# DBGSS register map
Vendor: Texas Instruments
Peripheral module from a debugger description file (folder CC27xxx10).
Registers are 32-bit, access per field, reset 0x0 unless marked. A register's access mark holds for its fields unless they carry their own. Offsets are as the file gives them; lines under a group give offsets from that group; [hi:lo] are bit positions; {n}, {i} and the like mark numbered series; 'fields as' and 'values as' point back to an identical list; <NAME> marks a mode.

## DBGSS
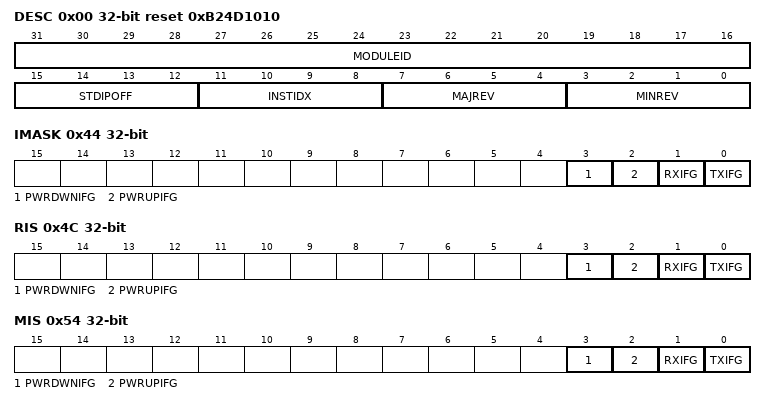
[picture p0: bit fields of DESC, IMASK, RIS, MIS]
0x00 DESC ro reset 0xB24D1010 — Description Register. This register provides IP module ID, revision information, instance index and standard MMR registers offset.
  [31:16] MODULEID — Module identifier used to uniquely identify this IP.
    0xFFFF=MAX (Maximum possible value); 0=MIN (Minimum value)
  [15:12] STDIPOFF — Standard IP MMR block offset. Standard IP MMRs are the set of from aggregated IRQ registers till DTB. 0: Standard IP MMRs do not exist 0x1-0xF: Standard IP MMRs begin at offset of (64*STDIPOFF from the base IP address) 0: STDIP MMRs do not exist 0x1-0xF: These MMRs begin at offset 64*STDIPOFF from IP base address
    15=MAX (Maximum possible value); 0=MIN (Minimum Value)
  [11:8] INSTIDX — IP Instance ID number. If multiple instances of IP exist in the device, this field can identify the instance number (0-15).
    15=MAX (Maximum possible value); 0=MIN (Minimum Value)
  [7:4] MAJREV — Major revision of IP (0-15).
    15=MAX (Maximum possible value); 0=MIN (Minimum Value)
  [3:0] MINREV — Minor revision of IP (0-15).
    15=MAX (Maximum possible value); 0=MIN (Minimum Value)
0x44 IMASK — Interrupt mask. This register selects interrupt sources which are allowed to pass from RIS to MIS when the corresponding bit-fields are set to 1.
  [3] PWRDWNIFG rw — PWRDWNIFG interrupt mask
    1=SET (Interrupt will request an interrupt service routine and corresponding bit in MIS will be set); 0=CLR (Interrupt is masked out)
  [2] PWRUPIFG rw — PWRUPIFG interrupt mask
    values as PWRDWNIFG
  [1] RXIFG rw — RXIFG interrupt mask
    values as PWRDWNIFG
  [0] TXIFG rw — TXIFG interrupt mask
    1=EN (Enable Interrupt Mask); 0=DIS (Disable Interrupt Mask)
0x4C RIS ro — Raw interrupt status. This register reflects the state of all pending interrupts, regardless of masking. This register allows the user to implement a poll scheme. A flag set in this register can be cleared by writing 1 to the corresponding ICLR register bit.
  [3] PWRDWNIFG — Raw interrupt status for PWRDWNIFG
    1=SET (PWRDWNIFG occurred); 0=CLR (PWRDWNIFG did not occur)
  [2] PWRUPIFG — Raw interrupt status for PWRUPIFG
    1=SET (PWRUPIFG occurred); 0=CLR (PWRUPIFG did not occur)
  [1] RXIFG — Raw interrupt status for RXIFG
    1=SET (RXIFG occurred); 0=CLR (RXIFG did not occur)
  [0] TXIFG — Raw interrupt status for TXIFG
    1=SET (TXIFG occurred); 0=CLR (TXIFG did not occur)
0x54 MIS ro — Masked interrupt status. This register is simply a bitwise AND of the contents of IMASK and RIS registers. A flag set in this register can be cleared by writing 1 to the corresponding ICLR register bit.
  [3] PWRDWNIFG — Masked interrupt status for PWRDWNIFG
    1=SET (PWRDWNIFG requests an interrupt service routine); 0=CLR (PWRDWNIFG did not request an interrupt service routine)
  [2] PWRUPIFG — Masked interrupt status for PWRUPIFG
    1=SET (PWRUPIFG requests an interrupt service routine); 0=CLR (PWRUPIFG did not request an interrupt service routine)
  [1] RXIFG — Masked interrupt status for RXIFG
    1=SET (RXIFG requests an interrupt service routine); 0=CLR (RXIFG did not request an interrupt service routine)
  [0] TXIFG — Masked interrupt status for TXIFG
    1=SET (TXIFG requests an interrupt service routine); 0=CLR (TXIFG did not request an interrupt service routine)
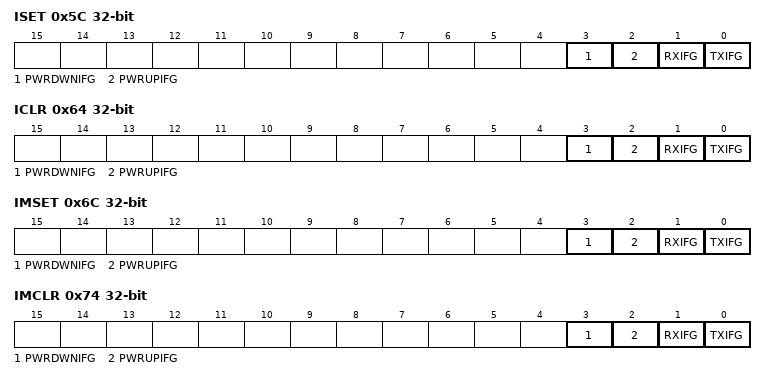
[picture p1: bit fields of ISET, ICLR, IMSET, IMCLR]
0x5C ISET — Interrupt set register. This register can be used by software for diagnostics and safety checking purposes. Writing a 1 to a bit in this register will set the event and the corresponding RIS bit also gets set. If the corresponding IMASK bit is set, then the corresponding MIS register bit also gets set.
  [all] fields
    1=SET (Set interrupt); 0=NOEFF (Writing a 0 has no effect)
  [3] PWRDWNIFG wo — Sets PWRDWNIFG in RIS register
  [2] PWRUPIFG wo — Sets PWRUPIFG in RIS register
  [1] RXIFG wo — Sets RXIFG in RIS register
  [0] TXIFG wo — Sets TXIFG in RIS register
0x64 ICLR — Interrupt clear register. This register allows software to clear interrupts. Writing a 1 to a bit in this register will clear the event and the corresponding RIS bit also gets cleared. If the corresponding IMASK bit is set, then the corresponding MIS register bit also gets cleared.
  [all] fields
    1=CLR (Clear interrupt); 0=NOEFF (Writing a 0 has no effect)
  [3] PWRDWNIFG wo — Clears PWRDWNIFG interrupt
  [2] PWRUPIFG wo — Clears PWRUPIFG interrupt
  [1] RXIFG wo — Clears RXIFG interrupt
  [0] TXIFG wo — Clears TXIFG interrupt
0x6C IMSET — Interrupt mask set register. Writing a 1 to a bit in this register will set the corresponding IMASK bit.
  [all] fields
    1=SET (Set interrupt mask); 0=NOEFF (Writing a 0 has no effect)
  [3] PWRDWNIFG wo — Set PWRDWNIFG interrupt mask
  [2] PWRUPIFG wo — Set PWRUPIFG interrupt mask
  [1] RXIFG wo — Set RXIFG interrupt mask
  [0] TXIFG wo — Set TXIFG interrupt mask
0x74 IMCLR — Interrupt mask clear register. Writing a 1 to a bit in this register will clear the corresponding IMASK bit.
  [3] PWRDWNIFG wo — Clears PWRDWNIFG interrupt mask
    1=CLR (IMASK bit corresponding to PWRDWNIFG is cleared); 0=NO_EFFECT (Writing a 0 has no effect)
  [2] PWRUPIFG wo — Clears PWRUPIFG interrupt mask
    1=CLR (IMASK bit corresponding to PWRUPIFG is cleared); 0=NO_EFFECT (Writing a 0 has no effect)
  [1] RXIFG wo — Clears RXIFG interrupt mask
    1=CLR (IMASK bit corresponding to RXIFG is cleared); 0=NO_EFFECT (Writing a 0 has no effect)
  [0] TXIFG wo — Clears TXIFG interrupt mask
    1=CLR (IMASK bit corresponding to TXIFG is cleared); 0=NO_EFFECT (Writing a 0 has no effect)
0x100 TXD ro — Transmit data register. This register is used for sending SACI (SECAP command interface) data from the host to the device. The host (SWD interface) can write this register. This updates the value of TXD, and sets TXCTL.TXDSTA = FULL The host should only write TXD while TXCTL.TXDSTA = EMPTY. If the host incorrectly writes TXD while TXCTL.TXDSTA = FULL, this will just update the value of TXD. The host (SWD interface) can read the TXD register. This does not affect TXCTL.TXDSTA. The device (boot code) can only read the TXD register. This sets TXCTL.TXDSTA = EMPTY. The device should only read TXD while TXCTL.TXDSTA = FULL. If the device incorrectly reads TXD while TXCTL.TXDSTA = EMPTY, this will just return the value of TXD. If the host writes TXD on the same clock cycle as the device reads TXD: The device reads the old TXD value. TXD is updated with the new value, and TXCTL.TXDSTA is set to FULL.
  [31:0] VAL — SACI command/parameter word. Valid value when TXCTL.TXDSTA=1. TXCTL.TXDSTA gets automatically cleared upon read.
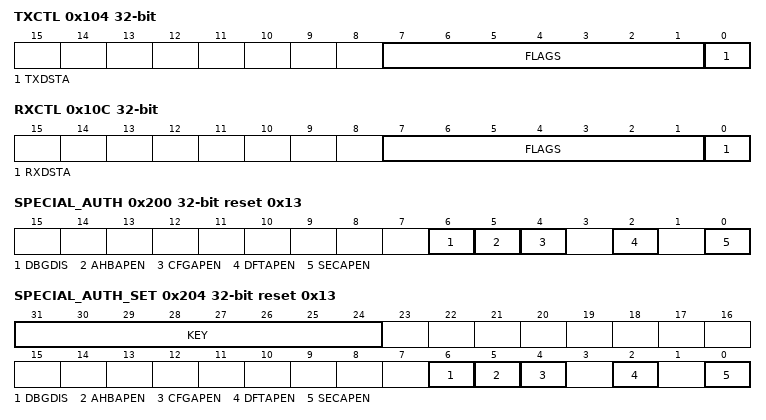
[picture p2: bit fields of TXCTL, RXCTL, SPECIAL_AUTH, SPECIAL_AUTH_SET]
0x104 TXCTL ro — Transmit control register. This register contains status of the TXD register (full/empty), and also software defined flags that are used by the SACI protocol. The host (SWD interface) can write the FLAGS field of the TXCTL register. The host (SWD interface) can read the TXCTL register. The device (boot code) can only read the TXCTL register.
  [7:1] FLAGS — Software defined flags that are used by the SACI protocol (host to device).
  [0] TXDSTA — Indicates whether the host has written a word to the TXD register, which can be read by the device: TXDSTA is automatically set upon write to TXD register in SECAP and automatically gets cleared upon read from TXD
    1=FULL (The TXD register contains a new SACI parameter word from the host, which can be read by the device.); 0=EMPTY (The TXD register does not contain a new SACI parameter word from the host, and should not be read by the device.)
0x108 RXD rw — Receive data register. This register is used to send SACI command response data from the device to the host. The device (boot code) can write the RXD register. This updates the value of RXD, and sets RXCTL.RXDSTA = FULL. The device should only write RXD while RXCTL.RXDSTA = EMPTY. If the device incorrectly writes RXD while RXCTL.RXDSTA = FULL, this will just update the value of RXD. The device (boot code) can read the RXD register in order to flush it. This sets RXCTL.RXDSTA = EMPTY. The host (SWD interface) can only read the RXD register. This sets RXCTL.RXDSTA = EMPTY. The host should only read RXD while RXCTL.RXDSTA = FULL. If the host incorrectly reads RXD while RXCTL.RXDSTA = EMPTY, this will just return the value of RXD. If the device writes RXD on the same clock cycle as the host reads RXD: The host reads the old RXD value. RXD is updated with the new value, and RXCTL.RXDSTA is set to FULL.
  [31:0] VAL — SACI command response word. RXCTL.RXDSTA automatically set upon write. RXCTL.RXDSTA automatically cleared upon read (flush operation).
0x10C RXCTL — Receive control register. This register contains status of the RXD register (full/empty), and also software defined flags that are used by the SACI protocol. The device (boot code) can write the FLAGS field of the RXCTL register. The device (boot code) can read the RXCTL register. The host (SWD interface) can only read the RXCTL register
  [7:1] FLAGS rw — Software defined flags that are used by the SACI protocol (device to host).
  [0] RXDSTA ro — Indicates whether the device has written a word to the RXD register, which can be read by the host: RXDSTA is automatically set upon write to RXD and automatically cleared upon read from RXD register of SECAP or RXD.
    1=FULL (The RXD register contains a new SACI response word from the device, which can be read by the host.); 0=EMPTY (The RXD register does not contain a new SACI response word from the device, and should not be read by the host.)
0x110 TXDPEEK ro — Transmit data peek register . This register is a read-only version of the TXD register that can be read by host and device without any side-effects. This register is used to peek at the values in TXD without affecting the FULL/EMPTY flag.
  [31:0] VAL — Transmit Data Peek Register. SACI command parameter word. TXCTL.TXDSTA not affected by read of TXDPEEK
0x114 RXDPEEK ro — Receive data peek register. The RXDPEEK register is a read-only version of the RXD register that can be read by host and device without any side-effects This register is used to peek at the values in Receive Data Register without affecting the FULL/EMPTY flag.
  [31:0] VAL — Receive Data Peek Register. SACI command response word. RXCTL.RXDSTA not affected by read of RXDPEEK
0x200 SPECIAL_AUTH ro reset 0x13 — This register indicates the status of different AP firewalls.
  [6] DBGDIS — Indicates status of DBGDIS.
    1=DIS (Disables debugging capability); 0=EN (Enables debugging capability.)
  [5] AHBAPEN — Indicates status of AHBAPEN
    1=EN (Enable AHB-AP); 0=DIS (Disable AHB-AP)
  [4] CFGAPEN — Indicates status of CFGAPEN
    1=EN (Enable CFG-AP); 0=DIS (Disable CFG-AP)
  [2] DFTAPEN — Indicates status of DFTAPEN
    1=EN (Enable DFT-TAP); 0=DIS (Disable DFT-TAP)
  [0] SECAPEN — Indicates status of SECAP
    1=EN (Enable SEC-AP); 0=DIS (Disable SEC-AP)
0x204 SPECIAL_AUTH_SET reset 0x13 — This register is used for setting bits in SPECIAL_AUTH register. This register is configured and locked during device boot.
  [31:24] KEY wo — This field must be configured with 0xA5 in order to access this register.
    165=_to_unlock_w_ (This field must be written with 0xA5 to be able to set any of the enable bits)
  [6] DBGDIS wo — This bit sets DBGDIS in SPECIAL_AUTH register.
    1=SET (SET DBGDIS); 0=NOEFF (Writing 0 has no effect)
  [5] AHBAPEN wo — This bit sets AHBAPEN in SPECIAL_AUTH register.
    1=SET (SET AHB-AP); 0=NOEFF (Writing 0 has no effect)
  [4] CFGAPEN wo — This bit sets CFGAPEN in SPECIAL_AUTH register.
    1=SET (Set CFGAPEN); 0=NOEFF (Writing 0 has no effect)
  [2] DFTAPEN wo — This bit sets DFTAPEN in SPECIAL_AUTH register.
    1=SET (Set DFTAPEN); 0=NOEFF (Writing 0 has no effect)
  [0] SECAPEN wo — This bit sets SECAPEN bit in SPECIAL_AUTH register.
    1=SET (Set SECAPEN); 0=NOEFF (Writing 0 has no effect)
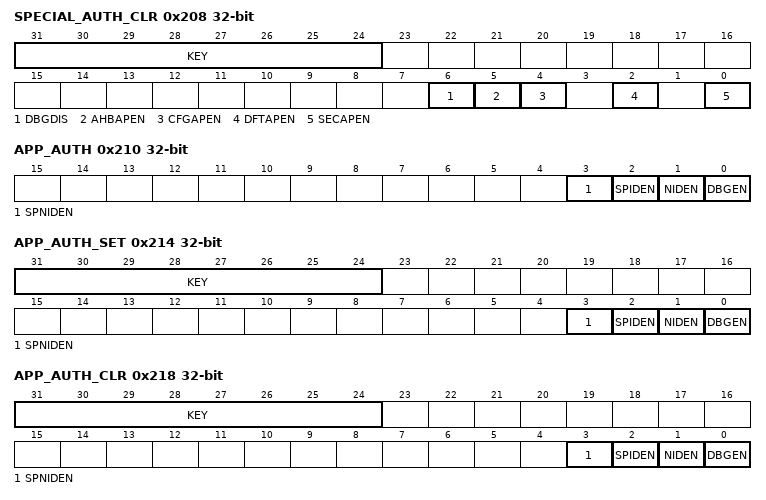
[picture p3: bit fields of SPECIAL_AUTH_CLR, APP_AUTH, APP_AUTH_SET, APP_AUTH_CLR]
0x208 SPECIAL_AUTH_CLR — This register is used for clearing bits in SPECIAL_AUTH register. This register is configured and locked during device boot.
  [31:24] KEY wo — This field must be configured with 0x22 in order to access this register.
    34=_to_unlock_w_ (This field must be written with 0x22 to be able to clear any of the enable bits)
  [6] DBGDIS wo — This bit clears DBGDIS in SPECIAL_AUTH register.
    1=CLR (Clear DBGDIS); 0=NOEFF (Writing 0 has no effect)
  [5] AHBAPEN wo — This bit clears AHBAPEN in SPECIAL_AUTH register.
    1=CLR (Clear AHBAPEN); 0=NOEFF (Writing 0 has no effect)
  [4] CFGAPEN wo — This bit clears CFGAPEN in SPECIAL_AUTH register.
    1=CLR (Clear CFGAPEN); 0=NOEFF (Writing 0 has no effect)
  [2] DFTAPEN wo — This bit clears DFTAPEN in SPECIAL_AUTH register.
    1=CLR (Clear DFTAPEN); 0=NOEFF (Writing 0 has no effect)
  [0] SECAPEN wo — This bit clears SECAPEN in SPECIAL_AUTH register.
    1=CLR (Clear SECAPEN); 0=NOEFF (Writing 0 has no effect)
0x210 APP_AUTH ro — This register indicates the debug privileges of ARM Cortex CPU.
  [3] SPNIDEN — Controls Secure non-invasive debug enable.
    1=EN (Secure non-invasive debug enabled); 0=DIS (Secure non-invasive debug disabled)
  [2] SPIDEN — Controls Secure invasive debug enable.
    1=EN (Secure invasive debug enabled); 0=DIS (Secure invasive debug disabled)
  [1] NIDEN — Controls non-invasive debug enable.
    1=EN (Non-invasive debug enabled); 0=DIS (Non-invasive debug disabled)
  [0] DBGEN — Controls invasive debug enable.
    1=EN (Invasive debug enabled); 0=DIS (Invasive debug disabled)
0x214 APP_AUTH_SET — This register is used for setting bits in APP_AUTH register. This register is configured and locked during device boot.
  [31:24] KEY wo — This field must be configured with 0x39 in order to access this register.
    57=_to_unlock_w_ (Write this value 0x39 to unlock writing to the APP_AUTH_SET register)
  [3] SPNIDEN wo — Sets SPNIDEN bit in APP_AUTH register.
    1=SET (Sets SPNIDEN); 0=NOEFF (Writing 0 has no effect)
  [2] SPIDEN wo — Sets SPIDEN bit in APP_AUTH register.
    1=SET (Sets SPIDEN); 0=NOEFF (Writing 0 has no effect)
  [1] NIDEN wo — Sets NIDEN bit in [APP_AUTH ]register.
    1=SET (Sets NIDEN); 0=NOEFF (Writing 0 has no effect)
  [0] DBGEN wo — Sets DBGEN bit in APP_AUTH register.
    1=SET (Sets DBGEN); 0=NOEFF (Writing 0 has no effect)
0x218 APP_AUTH_CLR — This register is used for clearing bits in APP_AUTH register. This register is configured and locked during device boot.
  [31:24] KEY wo — This field must be configured with 0x7D in order to access this register.
    125=_to_unlock_w_ (Write this value 0x7D to unlock writing to the APP_AUTH_CLR register)
  [3] SPNIDEN wo — Clears SPNIDEN bit in APP_AUTH register.
    1=CLR (Clears SPIDEN); 0=NOEFF (Writing 0 has no effect)
  [2] SPIDEN wo — Sets SPIDEN bit in APP_AUTH register.
    1=CLR (Clear SPIDEN); 0=NOEFF (Writing 0 has no effect)
  [1] NIDEN wo — Clears NIDEN bit in APP_AUTH register.
    1=CLR (Clears NIDEN); 0=NOEFF (Writing 0 has no effect)
  [0] DBGEN wo — Clears DBGEN bit in APP_AUTH register.
    1=CLR (Clears DBGEN); 0=NOEFF (Writing 0 has no effect)
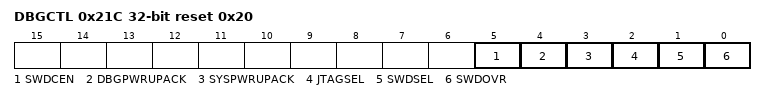
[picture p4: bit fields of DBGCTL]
0x21C DBGCTL reset 0x20 — Debug control register. This register is used for controlling debug connection and read out debug status.
  [5] SWDCEN rw — This bit is used to enable connection between SWD pads and IceMelter (wakeup circuit used for detecting debug probe)
    1=EN (Connection enabled); 0=DIS (Connection disabled)
  [4] DBGPWRUPACK ro — This bit field specifies the status of dbgpwrupack from pmctl.
    1=EN (dbgpwrupreq is acknowledged.); 0=DIS (dbgpwrupreq is not acknowledged)
  [3] SYSPWRUPACK ro — This bit field specify the status of syspwrupack from pmctl.
    1=EN (syspwrupreq is acknowledged); 0=DIS (syspwrupreq is not acknowledged)
  [2] JTAGSEL ro — This bit field specifies the status of JTAG MODE for TEST TAP.
    1=EN (TEST TAP enabled); 0=DIS (TEST TAP disabled)
  [1] SWDSEL ro — This bit field specifies the status of SWD MODE for connection.
    1=EN (debug connection enabled.); 0=DIS (debug connection disabled.)
  [0] SWDOVR rw — This bit is used for connecting to IO pads to SWCLK/IO on SW-DP through a software request and establish SWD connection without IceMelter trigger for debug purpose.
    1=DBGENA (Force 1 or debug enable mode in which SWD connection is established bypassing IceMelter sequence); 0=TRNSPRT (Transparent mode in which SWD connection is established via IceMelter Sequence.)
